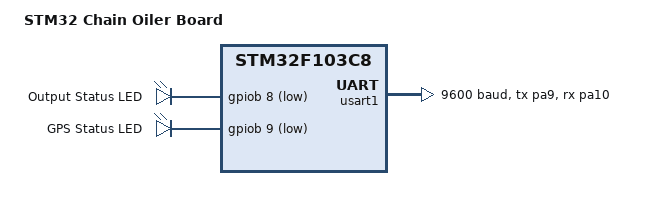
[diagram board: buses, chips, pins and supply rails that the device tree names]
/*
 * Copyright (c) 2019, embedjournal.com
 *
 * SPDX-License-Identifier: Apache-2.0
 */

/dts-v1/;
#include <st/f1/stm32f103X8.dtsi>
#include <st/f1/stm32f103r(8-b)tx-pinctrl.dtsi>

/ {
	model = "STM32 Chain Oiler Board";
	compatible = "st,stm32f103c8";

	chosen {
		/*
		zephyr,console = &usart2;
		zephyr,shell-uart = &usart2;
		*/
		zephyr,sram = &sram0;
		zephyr,flash = &flash0;
	};

	leds {
		compatible = "gpio-leds";
		led0: led_0 {
			gpios = <&gpiob 8 GPIO_ACTIVE_LOW>;
			label = "Output Status LED";
		};
		led1: led_1 {
			gpios = <&gpiob 9 GPIO_ACTIVE_LOW>;
			label = "GPS Status LED";
		};
	};

	aliases {
		gps-uart = &usart1;
		output-status-led = &led0;
		gps-status-led = &led1;
		led0 = &led1;
	};
};

&pinctrl {
	status = "okay";
	pb3_swo {
		pinmux = <STM32F1_PINMUX('B', 3, ALTERNATE, REMAP_FULL)>;
	};
};

&clk_hsi {
	status = "okay";
};

&pll {
	mul = <16>;
	clocks = <&clk_hsi>;
	status = "okay";
};

&rcc {
	clocks = <&pll>;
	clock-frequency = <DT_FREQ_M(64)>;
	ahb-prescaler = <1>;
	apb1-prescaler = <2>;
	apb2-prescaler = <1>;
};

&usart1 {
	status = "okay";
	pinctrl-0 = <&usart1_tx_pa9 &usart1_rx_pa10>;
	current-speed = <9600>;
};
